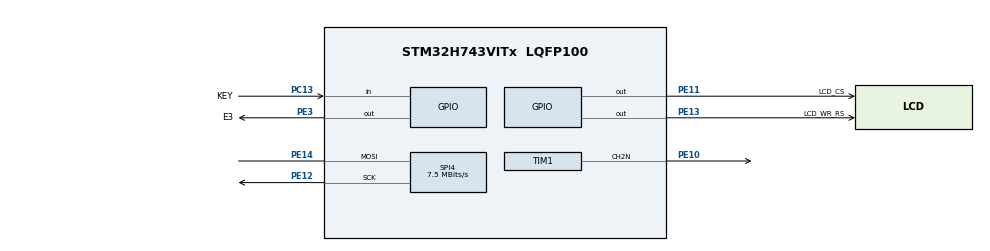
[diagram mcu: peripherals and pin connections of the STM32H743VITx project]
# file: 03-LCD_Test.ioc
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Mcu.Family=STM32H7
Mcu.Name=STM32H743VITx
Mcu.Package=LQFP100
NVIC.PriorityGroup=NVIC_PRIORITYGROUP_4
PA13\ (JTMS/SWDIO).Mode=Serial_Wire
PA13\ (JTMS/SWDIO).Signal=DEBUG_JTMS-SWDIO
PA14\ (JTCK/SWCLK).Mode=Serial_Wire
PA14\ (JTCK/SWCLK).Signal=DEBUG_JTCK-SWCLK
PC13.GPIO_Label=KEY
PC13.GPIO_PuPd=GPIO_PULLDOWN
PC13.Signal=GPIO_Input
PC14-OSC32_IN\ (OSC32_IN).Mode=LSE-External-Oscillator
PC14-OSC32_IN\ (OSC32_IN).Signal=RCC_OSC32_IN
PC15-OSC32_OUT\ (OSC32_OUT).Mode=LSE-External-Oscillator
PC15-OSC32_OUT\ (OSC32_OUT).Signal=RCC_OSC32_OUT
PE10.Mode=PWM Generation2 CH2N
PE10.Signal=TIM1_CH2N
PE11.GPIO_Label=LCD_CS
PE11.GPIO_Speed=GPIO_SPEED_FREQ_VERY_HIGH
PE11.PinState=GPIO_PIN_SET
PE11.Signal=GPIO_Output
PE12.GPIO_Speed=GPIO_SPEED_FREQ_HIGH
PE12.Mode=Simplex_Bidirectional_Master
PE12.Signal=SPI4_SCK
PE13.GPIO_Label=LCD_WR_RS
PE13.GPIO_Speed=GPIO_SPEED_FREQ_VERY_HIGH
PE13.PinState=GPIO_PIN_SET
PE13.Signal=GPIO_Output
PE14.GPIO_Speed=GPIO_SPEED_FREQ_HIGH
PE14.Mode=Simplex_Bidirectional_Master
PE14.Signal=SPI4_MOSI
PE3.GPIO_Label=E3
PE3.PinState=GPIO_PIN_RESET
PE3.Signal=GPIO_Output
PH0-OSC_IN\ (PH0).Mode=HSE-External-Oscillator
PH0-OSC_IN\ (PH0).Signal=RCC_OSC_IN
PH1-OSC_OUT\ (PH1).Mode=HSE-External-Oscillator
PH1-OSC_OUT\ (PH1).Signal=RCC_OSC_OUT
ProjectManager.HeapSize=0x200
ProjectManager.StackSize=0x400
ProjectManager.TargetToolchain=STM32CubeIDE
RCC.ADCFreq_Value=83333333.33333333
RCC.APB1Freq_Value=60000000
RCC.APB2Freq_Value=60000000
RCC.APB3Freq_Value=60000000
RCC.APB4Freq_Value=60000000
RCC.CortexFreq_Value=240000000
RCC.D1PPRE=RCC_APB3_DIV2
RCC.D2PPRE1=RCC_APB1_DIV2
RCC.D2PPRE2=RCC_APB2_DIV2
RCC.D3PPRE=RCC_APB4_DIV2
RCC.DIVM1=5
RCC.DIVM2=6
RCC.DIVN1=96
RCC.DIVN2=40
RCC.DIVQ2=1
RCC.HCLKFreq_Value=120000000
RCC.HPRE=RCC_HCLK_DIV2
RCC.HSE_VALUE=25000000
RCC.PLL2FRACN=0
RCC.PLL3FRACN=0
RCC.PLLFRACN=0
RCC.PLLSourceVirtual=RCC_PLLSOURCE_HSE
RCC.PWR_Regulator_Voltage_Scale=PWR_REGULATOR_VOLTAGE_SCALE0
RCC.RTCClockSelection=RCC_RTCCLKSOURCE_LSE
RCC.SYSCLKFreq_VALUE=240000000
RCC.SYSCLKSource=RCC_SYSCLKSOURCE_PLLCLK
RCC.USBFreq_Value=240000000
RTC.Hours=12
RTC.Month=RTC_MONTH_JUNE
RTC.Year=20
SPI4.BaudRatePrescaler=SPI_BAUDRATEPRESCALER_8
SPI4.CalculateBaudRate=7.5 MBits/s
SPI4.DataSize=SPI_DATASIZE_8BIT
SPI4.Direction=SPI_DIRECTION_1LINE
SPI4.Mode=SPI_MODE_MASTER
SPI4.VirtualType=VM_MASTER
TIM1.Channel-PWM\ Generation2\ CH2N=TIM_CHANNEL_2
TIM1.OCNPolarity_2=TIM_OCNPOLARITY_LOW
TIM1.Period=1000-1
TIM1.Prescaler=12-1
VP_RTC_VS_RTC_Activate.Mode=RTC_Enabled
VP_RTC_VS_RTC_Calendar.Mode=RTC_Calendar
board=custom

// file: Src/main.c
/* USER CODE BEGIN Header */
/**
  ******************************************************************************
  * @file           : main.c
  * @brief          : Main program body
  ******************************************************************************
  * @attention
  *
  * Copyright (c) 2026 STMicroelectronics.
  * All rights reserved.
  *
  * This software is licensed under terms that can be found in the LICENSE file
  * in the root directory of this software component.
  * If no LICENSE file comes with this software, it is provided AS-IS.
  *
  ******************************************************************************
  */
/* USER CODE END Header */
#include "main.h"
#include "rtc.h"
#include "spi.h"
#include "tim.h"
#include "gpio.h"

/* USER CODE BEGIN Includes */
#include "lcd.h"
/* USER CODE END Includes */

void SystemClock_Config(void);

int main(void)
{

  /* USER CODE BEGIN 1 */
	// определяем где выполняется программа, и корректируем расположение
	// таблицы векторов
	uint32_t retPCasm(void); // небольшая функция для определения где
	// выполняется программа в FLASH или RAM
	if ((retPCasm() & 0x24000000) != 0)
	{
		*((uint32_t *)0xe000ed08) = 0x24000000; /* FlagDebugInRAM=1;*/
	}
	/* Enable I-Cache */
	SCB_EnableICache();

	/* Enable D-Cache */
	SCB_EnableDCache();

  /* USER CODE END 1 */

  /* MCU Configuration--------------------------------------------------------*/

  /* Reset of all peripherals, Initializes the Flash interface and the Systick. */
  HAL_Init();

  /* Configure the system clock */
  SystemClock_Config();

  /* Initialize all configured peripherals */
  MX_GPIO_Init();
  MX_RTC_Init();
  MX_SPI4_Init();
  MX_TIM1_Init();
  /* USER CODE BEGIN 2 */
	LCD_Test();

  /* USER CODE END 2 */

  /* Infinite loop */
  while (1)
  {

  }
}

void SystemClock_Config(void)
{
  RCC_OscInitTypeDef RCC_OscInitStruct = {0};
  RCC_ClkInitTypeDef RCC_ClkInitStruct = {0};

  /** Supply configuration update enable
  */
  HAL_PWREx_ConfigSupply(PWR_LDO_SUPPLY);

  /** Configure the main internal regulator output voltage
  */
  __HAL_PWR_VOLTAGESCALING_CONFIG(PWR_REGULATOR_VOLTAGE_SCALE0);

  while(!__HAL_PWR_GET_FLAG(PWR_FLAG_VOSRDY)) {}

  /** Configure LSE Drive Capability
  */
  HAL_PWR_EnableBkUpAccess();
  __HAL_RCC_LSEDRIVE_CONFIG(RCC_LSEDRIVE_LOW);

  /** Initializes the RCC Oscillators according to the specified parameters
  * in the RCC_OscInitTypeDef structure.
  */
  RCC_OscInitStruct.OscillatorType = RCC_OSCILLATORTYPE_HSE|RCC_OSCILLATORTYPE_LSE;
  RCC_OscInitStruct.HSEState = RCC_HSE_ON;
  RCC_OscInitStruct.LSEState = RCC_LSE_ON;
  RCC_OscInitStruct.PLL.PLLState = RCC_PLL_ON;
  RCC_OscInitStruct.PLL.PLLSource = RCC_PLLSOURCE_HSE;
  RCC_OscInitStruct.PLL.PLLM = 5;
  RCC_OscInitStruct.PLL.PLLN = 96;
  RCC_OscInitStruct.PLL.PLLP = 2;
  RCC_OscInitStruct.PLL.PLLQ = 2;
  RCC_OscInitStruct.PLL.PLLR = 2;
  RCC_OscInitStruct.PLL.PLLRGE = RCC_PLL1VCIRANGE_2;
  RCC_OscInitStruct.PLL.PLLVCOSEL = RCC_PLL1VCOWIDE;
  RCC_OscInitStruct.PLL.PLLFRACN = 0;
  if (HAL_RCC_OscConfig(&RCC_OscInitStruct) != HAL_OK)
  {
    Error_Handler();
  }

  /** Initializes the CPU, AHB and APB buses clocks
  */
  RCC_ClkInitStruct.ClockType = RCC_CLOCKTYPE_HCLK|RCC_CLOCKTYPE_SYSCLK
                              |RCC_CLOCKTYPE_PCLK1|RCC_CLOCKTYPE_PCLK2
                              |RCC_CLOCKTYPE_D3PCLK1|RCC_CLOCKTYPE_D1PCLK1;
  RCC_ClkInitStruct.SYSCLKSource = RCC_SYSCLKSOURCE_PLLCLK;
  RCC_ClkInitStruct.SYSCLKDivider = RCC_SYSCLK_DIV1;
  RCC_ClkInitStruct.AHBCLKDivider = RCC_HCLK_DIV2;
  RCC_ClkInitStruct.APB3CLKDivider = RCC_APB3_DIV2;
  RCC_ClkInitStruct.APB1CLKDivider = RCC_APB1_DIV2;
  RCC_ClkInitStruct.APB2CLKDivider = RCC_APB2_DIV2;
  RCC_ClkInitStruct.APB4CLKDivider = RCC_APB4_DIV2;

  if (HAL_RCC_ClockConfig(&RCC_ClkInitStruct, FLASH_LATENCY_1) != HAL_OK)
  {
    Error_Handler();
  }
}

void Error_Handler(void)
{
  __disable_irq();
  while (1)
  {
  }
}
